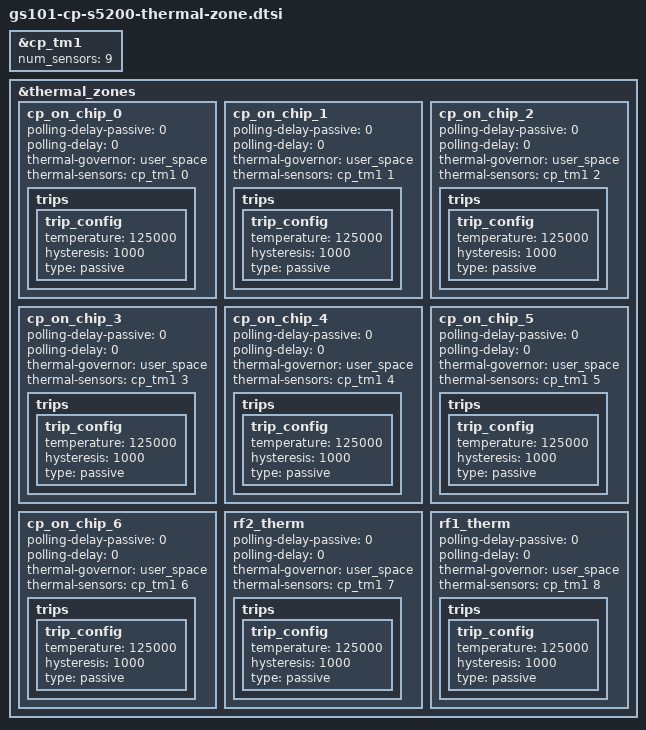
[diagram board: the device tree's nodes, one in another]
// SPDX-License-Identifier: GPL-2.0-only
/*
 * CP thermal zones
 *
 * Copyright 2020 Google, LLC.
 */

#include <dt-bindings/thermal/thermal.h>

&cp_tm1 {
	num_sensors = <9>;
};

&thermal_zones {
	cp_on_chip_0 {
		polling-delay-passive = <0>;
		polling-delay = <0>;
		thermal-governor = "user_space";
		thermal-sensors = <&cp_tm1 0>;
		trips {
			trip_config {
				temperature = <125000>;
				hysteresis = <1000>;
				type = "passive";
			};
		};
	};
	cp_on_chip_1 {
		polling-delay-passive = <0>;
		polling-delay = <0>;
		thermal-governor = "user_space";
		thermal-sensors = <&cp_tm1 1>;
		trips {
			trip_config {
				temperature = <125000>;
				hysteresis = <1000>;
				type = "passive";
			};
		};
	};
	cp_on_chip_2 {
		polling-delay-passive = <0>;
		polling-delay = <0>;
		thermal-governor = "user_space";
		thermal-sensors = <&cp_tm1 2>;
		trips {
			trip_config {
				temperature = <125000>;
				hysteresis = <1000>;
				type = "passive";
			};
		};
	};
	cp_on_chip_3 {
		polling-delay-passive = <0>;
		polling-delay = <0>;
		thermal-governor = "user_space";
		thermal-sensors = <&cp_tm1 3>;
		trips {
			trip_config {
				temperature = <125000>;
				hysteresis = <1000>;
				type = "passive";
			};
		};
	};
	cp_on_chip_4 {
		polling-delay-passive = <0>;
		polling-delay = <0>;
		thermal-governor = "user_space";
		thermal-sensors = <&cp_tm1 4>;
		trips {
			trip_config {
				temperature = <125000>;
				hysteresis = <1000>;
				type = "passive";
			};
		};
	};
	cp_on_chip_5 {
		polling-delay-passive = <0>;
		polling-delay = <0>;
		thermal-governor = "user_space";
		thermal-sensors = <&cp_tm1 5>;
		trips {
			trip_config {
				temperature = <125000>;
				hysteresis = <1000>;
				type = "passive";
			};
		};
	};
	cp_on_chip_6 {
		polling-delay-passive = <0>;
		polling-delay = <0>;
		thermal-governor = "user_space";
		thermal-sensors = <&cp_tm1 6>;
		trips {
			trip_config {
				temperature = <125000>;
				hysteresis = <1000>;
				type = "passive";
			};
		};
	};
	rf2_therm {
		polling-delay-passive = <0>;
		polling-delay = <0>;
		thermal-governor = "user_space";
		thermal-sensors = <&cp_tm1 7>;
		trips {
			trip_config {
				temperature = <125000>;
				hysteresis = <1000>;
				type = "passive";
			};
		};
	};
	rf1_therm {
		polling-delay-passive = <0>;
		polling-delay = <0>;
		thermal-governor = "user_space";
		thermal-sensors = <&cp_tm1 8>;
		trips {
			trip_config {
				temperature = <125000>;
				hysteresis = <1000>;
				type = "passive";
			};
		};
	};
};
